# AT32F456xx_v2 register map
Vendor: Keil; Series: AT32F456; File version: 1.0
CPU: CM4 r0p1, little endian, no MPU, FPU, 4 interrupt priority bits
Registers are 32-bit, read-write, reset 0x0 unless marked. A register's access mark holds for its fields unless they carry their own. Offsets are from the block's base; [hi:lo] are bit positions; {n}, {i} and the like mark numbered series.

## SDIO1 — Secure digital input/output interface
Base 0x40024C00
Same registers: SDIO2 0x50061000
0x00 PWRCTRL — Bits 1:0 = PWRCTRL: Power supply control bits
  [1:0] PS — Power switch
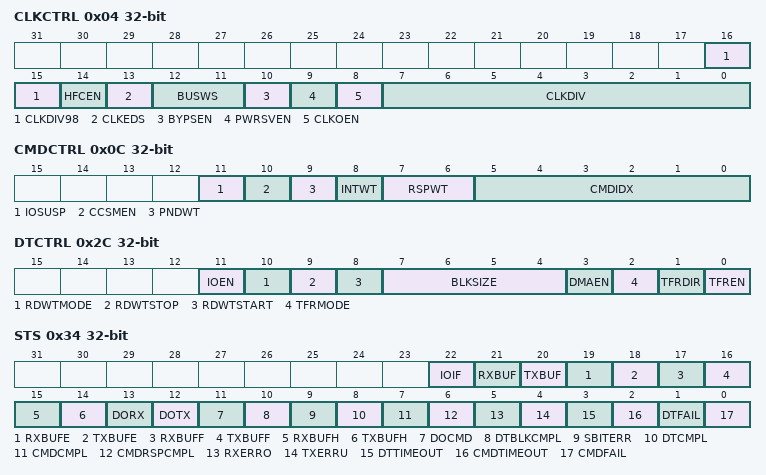
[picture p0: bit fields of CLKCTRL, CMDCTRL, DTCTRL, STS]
0x04 CLKCTRL — SD clock control register (SDIO_CLKCTRL)
  [16:15] CLKDIV98 — Clock divide factor bit9 and bit8
  [14] HFCEN — Hardware flow control enable
  [13] CLKEDS — SDIO_CK edge selection bit
  [12:11] BUSWS — Bus width selection
  [10] BYPSEN — Clock divider bypass enable bit
  [9] PWRSVEN — Power saving mode enable
  [8] CLKOEN — Clock output enable
  [7:0] CLKDIV — Clock division
0x08 ARGU — Bits 31:0 = : Command argument
  [31:0] ARGU — Command argument
0x0C CMDCTRL — SDIO command control register (SDIO_CMDCTRL)
  [11] IOSUSP — SD I/O suspend command
  [10] CCSMEN — Command channel state machine
  [9] PNDWT — CCSM wait for end of transfer
  [8] INTWT — CCSM wait for interrupt
  [7:6] RSPWT — Wait for response
  [5:0] CMDIDX
0x10 RSPCMD ro — SDIO command register
  [5:0] RSPCMD
0x14 RSP1 ro — Bits 31:0 = CARDSTATUS1
  [31:0] CARDSTS1 — CARDSTATUS1
{0x10+4i} RSP{i} ro (i=2..4) — Bits 31:0 = CARDSTATUS{i}
  [31:0] CARDSTS2 — CARDSTATUS{i}
0x24 DTTMR — Bits 31:0 = TIMEOUT: Data timeout period
  [31:0] TIMEOUT — Data timeout period
0x28 DTLEN — Bits 24:0 = DATALENGTH: Data length value
  [24:0] DTLEN — Data length value
0x2C DTCTRL — SDIO data control register (SDIO_DCTRL)
  [11] IOEN — SD I/O function enable
  [10] RDWTMODE — RWMOD
  [9] RDWTSTOP — PWSTOP
  [8] RDWTSTART — PWSTART
  [7:4] BLKSIZE — DBLOCKSIZE
  [3] DMAEN
  [2] TFRMODE — DTMODE
  [1] TFRDIR — DTDIR
  [0] TFREN — DTEN
0x30 DTCNT ro — Bits 24:0 = DATACOUNT: Data count value
  [24:0] CNT — Data count value
0x34 STS ro — SDIO status register (SDIO_STA)
  [22] IOIF — SD I/O interrupt
  [21] RXBUF — Rx data vaild
  [20] TXBUF — Tx data vaild
  [19] RXBUFE — Rx buffer empty
  [18] TXBUFE — Tx buffer empty
  [17] RXBUFF — Rx buffer full
  [16] TXBUFF — Tx buffer full
  [15] RXBUFH — Rx buffer half empty
  [14] TXBUFH — Tx buffer half empty
  [13] DORX — Data receive in progress
  [12] DOTX — Data transmit in progress
  [11] DOCMD — Command transfer in progress
  [10] DTBLKCMPL — Data block sent
  [9] SBITERR — Start bit error
  [8] DTCMPL — Data sent
  [7] CMDCMPL — Command sent
  [6] CMDRSPCMPL — Command response complete
  [5] RXERRO — Rx over run error
  [4] TXERRU — Tx under run error
  [3] DTTIMEOUT — Data timeout
  [2] CMDTIMEOUT — Command timeout
  [1] DTFAIL — Data crc fail
  [0] CMDFAIL — Command crc fail
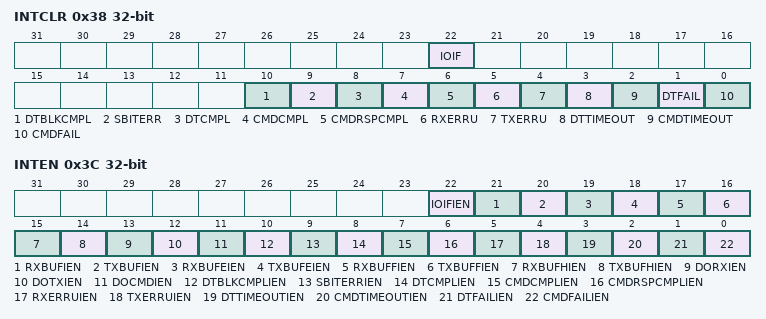
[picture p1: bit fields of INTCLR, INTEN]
0x38 INTCLR — SDIO interrupt clear register (SDIO_INTCLR)
  [22] IOIF — SD I/O interrupt flag clear
  [10] DTBLKCMPL — Data block sent clear
  [9] SBITERR — Start bit error flag clear
  [8] DTCMPL — Data sent flag clear
  [7] CMDCMPL — Command sent flag clear
  [6] CMDRSPCMPL — Command response complete flag clear
  [5] RXERRU — Rx over run error flag clear
  [4] TXERRU — Tx under run error flag clear
  [3] DTTIMEOUT — Data timeout flag clear
  [2] CMDTIMEOUT — Command timeout flag clear
  [1] DTFAIL — Data crc fail flag clear
  [0] CMDFAIL — Command crc fail flag clear
0x3C INTEN — SDIO mask register (SDIO_MASK)
  [22] IOIFIEN — SD I/O interrupt enable
  [21] RXBUFIEN — Rx buffer data vaild interrupt enable
  [20] TXBUFIEN — Tx buffer data vaild interrupt enable
  [19] RXBUFEIEN — Rx buffer empty interrupt enable
  [18] TXBUFEIEN — Tx buffer empty interrupt enable
  [17] RXBUFFIEN — Rx buffer full interrupt enable
  [16] TXBUFFIEN — Tx buffer full interrupt enable
  [15] RXBUFHIEN — Rx buffer half empty interrupt enable
  [14] TXBUFHIEN — Tx buffer half empty interrupt enable
  [13] DORXIEN — Data receive acting interrupt enable
  [12] DOTXIEN — Data transmit acting interrupt enable
  [11] DOCMDIEN — Command acting interrupt enable
  [10] DTBLKCMPLIEN — Data block sent complete interrupt enable
  [9] SBITERRIEN — Start bit error interrupt enable
  [8] DTCMPLIEN — Data sent complete interrupt enable
  [7] CMDCMPLIEN — Command sent complete interrupt enable
  [6] CMDRSPCMPLIEN — Command response complete interrupt enable
  [5] RXERRUIEN — Rx over run interrupt enable
  [4] TXERRUIEN — Tx under run interrupt enable
  [3] DTTIMEOUTIEN — Data timeout interrupt enable
  [2] CMDTIMEOUTIEN — Command timeout interrupt enable
  [1] DTFAILIEN — Data crc fail interrupt enable
  [0] CMDFAILIEN — Command crc fail interrupt enable
0x48 BUFCNT ro — Bits 23:0 = BUFCOUNT: Remaining number of words to be written to or read from the FIFO
  [23:0] CNT — FIF0COUNT
0x80 BUF — bits 31:0 = Buffer Data: Receive and transmit buffer data
  [31:0] DT — Buffer data

## Notices in the file
Copyright (C) 2012-2014 ARM Limited. All rights reserved.
Purpose: System Viewer Description (SVD) Example (Schema Version 1.1)
This is a description of a none-existent and incomplete device
for demonstration purposes only.
Redistribution and use in source and binary forms, with or without
modification, are permitted provided that the following conditions are met:
- Redistributions of source code must retain the above copyright
notice, this list of conditions and the following disclaimer.
- Redistributions in binary form must reproduce the above copyright
notice, this list of conditions and the following disclaimer in the
documentation and/or other materials provided with the distribution.
- Neither the name of ARM nor the names of its contributors may be used
to endorse or promote products derived from this software without
specific prior written permission.
THIS SOFTWARE IS PROVIDED BY THE COPYRIGHT HOLDERS AND CONTRIBUTORS "AS IS"
AND ANY EXPRESS OR IMPLIED WARRANTIES, INCLUDING, BUT NOT LIMITED TO, THE
IMPLIED WARRANTIES OF MERCHANTABILITY AND FITNESS FOR A PARTICULAR PURPOSE
ARE DISCLAIMED. IN NO EVENT SHALL COPYRIGHT HOLDERS AND CONTRIBUTORS BE
LIABLE FOR ANY DIRECT, INDIRECT, INCIDENTAL, SPECIAL, EXEMPLARY, OR
CONSEQUENTIAL DAMAGES (INCLUDING, BUT NOT LIMITED TO, PROCUREMENT OF
SUBSTITUTE GOODS OR SERVICES; LOSS OF USE, DATA, OR PROFITS; OR BUSINESS
INTERRUPTION) HOWEVER CAUSED AND ON ANY THEORY OF LIABILITY, WHETHER IN
CONTRACT, STRICT LIABILITY, OR TORT (INCLUDING NEGLIGENCE OR OTHERWISE)
ARISING IN ANY WAY OUT OF THE USE OF THIS SOFTWARE, EVEN IF ADVISED OF THE
POSSIBILITY OF SUCH DAMAGE.
